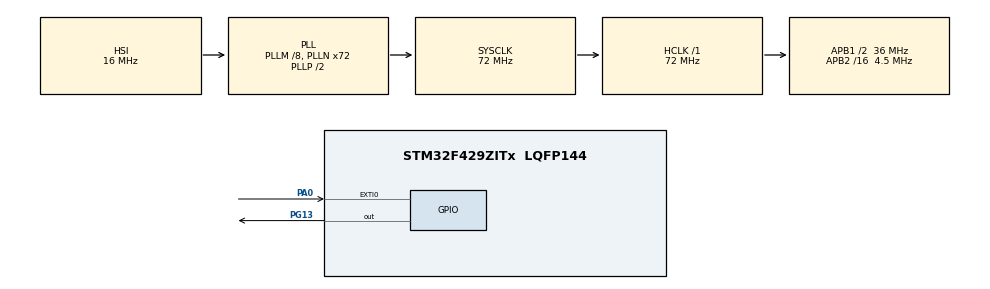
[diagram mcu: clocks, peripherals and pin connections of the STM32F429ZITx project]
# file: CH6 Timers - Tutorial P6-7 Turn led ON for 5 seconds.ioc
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Mcu.Family=STM32F4
Mcu.Name=STM32F429ZITx
Mcu.Package=LQFP144
NVIC.EXTI0_IRQn=true\:0\:0\:false\:false\:true\:true\:true\:true
NVIC.PriorityGroup=NVIC_PRIORITYGROUP_0
NVIC.TIM1_CC_IRQn=true\:0\:0\:false\:false\:true\:true\:true\:true
PA0/WKUP.Signal=GPXTI0
PG13.Signal=GPIO_Output
ProjectManager.HeapSize=0x200
ProjectManager.StackSize=0x400
ProjectManager.TargetToolchain=STM32CubeIDE
RCC.48MHZClocksFreq_Value=20571428.57142857
RCC.AHBFreq_Value=72000000
RCC.APB1CLKDivider=RCC_HCLK_DIV2
RCC.APB1Freq_Value=36000000
RCC.APB1TimFreq_Value=72000000
RCC.APB2CLKDivider=RCC_HCLK_DIV16
RCC.APB2Freq_Value=4500000
RCC.APB2TimFreq_Value=9000000
RCC.CortexFreq_Value=72000000
RCC.HCLKFreq_Value=72000000
RCC.HSE_VALUE=8000000
RCC.HSI_VALUE=16000000
RCC.LSE_VALUE=32768
RCC.PLLM=8
RCC.PLLN=72
RCC.PLLQ=7
RCC.SYSCLKFreq_VALUE=72000000
RCC.SYSCLKSource=RCC_SYSCLKSOURCE_PLLCLK
RCC.VCOOutputFreq_Value=144000000
TIM1.Channel-Output\ Compare1\ No\ Output=TIM_CHANNEL_1
TIM1.Period=20000-1
TIM1.Prescaler=9000-1
TIM1.Pulse-Output\ Compare1\ No\ Output=5000-1
VP_TIM1_VS_ClockSourceINT.Mode=Internal
VP_TIM1_VS_no_output1.Mode=Output Compare1 No Output
board=STM32F429I-DISC1

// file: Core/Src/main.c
/* USER CODE BEGIN Header */
/**
  ******************************************************************************
  * @file           : main.c
  * @brief          : Main program body
  ******************************************************************************
  * @attention
  *
  * Copyright (c) 2023 STMicroelectronics.
  * All rights reserved.
  *
  * This software is licensed under terms that can be found in the LICENSE file
  * in the root directory of this software component.
  * If no LICENSE file comes with this software, it is provided AS-IS.
  *
  ******************************************************************************
  */

 	/* 6 Timers - Problems: ******************************************
	* Tutorial P6-7
	*
	Form a project with the following specifications. When the user presses the
	button on the STM32F4 board, the green LED on the board turns on. The LED
	should turn off after 5 s
	***************************************************************************/
/* USER CODE END Header */
#include "main.h"

TIM_HandleTypeDef htim1;

/* USER CODE BEGIN PV */
uint32_t elapsedtime, TIM_freq;
/* USER CODE END PV */

void SystemClock_Config(void);
static void MX_GPIO_Init(void);
static void MX_TIM1_Init(void);

int main(void)
{

  /* MCU Configuration--------------------------------------------------------*/

  /* Reset of all peripherals, Initializes the Flash interface and the Systick. */
  HAL_Init();

  /* Configure the system clock */
  SystemClock_Config();

  /* Initialize all configured peripherals */
  MX_GPIO_Init();
  MX_TIM1_Init();

  /* Infinite loop */
  while (1)
  {

  }
}

void SystemClock_Config(void)
{
  RCC_OscInitTypeDef RCC_OscInitStruct = {0};
  RCC_ClkInitTypeDef RCC_ClkInitStruct = {0};

  /** Configure the main internal regulator output voltage
  */
  __HAL_RCC_PWR_CLK_ENABLE();
  __HAL_PWR_VOLTAGESCALING_CONFIG(PWR_REGULATOR_VOLTAGE_SCALE3);

  /** Initializes the RCC Oscillators according to the specified parameters
  * in the RCC_OscInitTypeDef structure.
  */
  RCC_OscInitStruct.OscillatorType = RCC_OSCILLATORTYPE_HSI;
  RCC_OscInitStruct.HSIState = RCC_HSI_ON;
  RCC_OscInitStruct.HSICalibrationValue = RCC_HSICALIBRATION_DEFAULT;
  RCC_OscInitStruct.PLL.PLLState = RCC_PLL_ON;
  RCC_OscInitStruct.PLL.PLLSource = RCC_PLLSOURCE_HSI;
  RCC_OscInitStruct.PLL.PLLM = 8;
  RCC_OscInitStruct.PLL.PLLN = 72;
  RCC_OscInitStruct.PLL.PLLP = RCC_PLLP_DIV2;
  RCC_OscInitStruct.PLL.PLLQ = 7;
  if (HAL_RCC_OscConfig(&RCC_OscInitStruct) != HAL_OK)
  {
    Error_Handler();
  }

  /** Initializes the CPU, AHB and APB buses clocks
  */
  RCC_ClkInitStruct.ClockType = RCC_CLOCKTYPE_HCLK|RCC_CLOCKTYPE_SYSCLK
                              |RCC_CLOCKTYPE_PCLK1|RCC_CLOCKTYPE_PCLK2;
  RCC_ClkInitStruct.SYSCLKSource = RCC_SYSCLKSOURCE_PLLCLK;
  RCC_ClkInitStruct.AHBCLKDivider = RCC_SYSCLK_DIV1;
  RCC_ClkInitStruct.APB1CLKDivider = RCC_HCLK_DIV2;
  RCC_ClkInitStruct.APB2CLKDivider = RCC_HCLK_DIV16;

  if (HAL_RCC_ClockConfig(&RCC_ClkInitStruct, FLASH_LATENCY_2) != HAL_OK)
  {
    Error_Handler();
  }
}

static void MX_TIM1_Init(void)
{

  TIM_ClockConfigTypeDef sClockSourceConfig = {0};
  TIM_MasterConfigTypeDef sMasterConfig = {0};
  TIM_OC_InitTypeDef sConfigOC = {0};
  TIM_BreakDeadTimeConfigTypeDef sBreakDeadTimeConfig = {0};

  htim1.Instance = TIM1;
  htim1.Init.Prescaler = 9000-1;
  htim1.Init.CounterMode = TIM_COUNTERMODE_UP;
  htim1.Init.Period = 20000-1;
  htim1.Init.ClockDivision = TIM_CLOCKDIVISION_DIV1;
  htim1.Init.RepetitionCounter = 0;
  htim1.Init.AutoReloadPreload = TIM_AUTORELOAD_PRELOAD_DISABLE;
  if (HAL_TIM_Base_Init(&htim1) != HAL_OK)
  {
    Error_Handler();
  }
  sClockSourceConfig.ClockSource = TIM_CLOCKSOURCE_INTERNAL;
  if (HAL_TIM_ConfigClockSource(&htim1, &sClockSourceConfig) != HAL_OK)
  {
    Error_Handler();
  }
  if (HAL_TIM_OC_Init(&htim1) != HAL_OK)
  {
    Error_Handler();
  }
  sMasterConfig.MasterOutputTrigger = TIM_TRGO_RESET;
  sMasterConfig.MasterSlaveMode = TIM_MASTERSLAVEMODE_DISABLE;
  if (HAL_TIMEx_MasterConfigSynchronization(&htim1, &sMasterConfig) != HAL_OK)
  {
    Error_Handler();
  }
  sConfigOC.OCMode = TIM_OCMODE_TIMING;
  sConfigOC.Pulse = 5000-1;
  sConfigOC.OCPolarity = TIM_OCPOLARITY_HIGH;
  sConfigOC.OCNPolarity = TIM_OCNPOLARITY_HIGH;
  sConfigOC.OCFastMode = TIM_OCFAST_DISABLE;
  sConfigOC.OCIdleState = TIM_OCIDLESTATE_RESET;
  sConfigOC.OCNIdleState = TIM_OCNIDLESTATE_RESET;
  if (HAL_TIM_OC_ConfigChannel(&htim1, &sConfigOC, TIM_CHANNEL_1) != HAL_OK)
  {
    Error_Handler();
  }
  sBreakDeadTimeConfig.OffStateRunMode = TIM_OSSR_DISABLE;
  sBreakDeadTimeConfig.OffStateIDLEMode = TIM_OSSI_DISABLE;
  sBreakDeadTimeConfig.LockLevel = TIM_LOCKLEVEL_OFF;
  sBreakDeadTimeConfig.DeadTime = 0;
  sBreakDeadTimeConfig.BreakState = TIM_BREAK_DISABLE;
  sBreakDeadTimeConfig.BreakPolarity = TIM_BREAKPOLARITY_HIGH;
  sBreakDeadTimeConfig.AutomaticOutput = TIM_AUTOMATICOUTPUT_DISABLE;
  if (HAL_TIMEx_ConfigBreakDeadTime(&htim1, &sBreakDeadTimeConfig) != HAL_OK)
  {
    Error_Handler();
  }

}

static void MX_GPIO_Init(void)
{
  GPIO_InitTypeDef GPIO_InitStruct = {0};

  /* GPIO Ports Clock Enable */
  __HAL_RCC_GPIOA_CLK_ENABLE();
  __HAL_RCC_GPIOG_CLK_ENABLE();

  /*Configure GPIO pin Output Level */
  HAL_GPIO_WritePin(GPIOG, GPIO_PIN_13, GPIO_PIN_RESET);

  /*Configure GPIO pin : PA0 */
  GPIO_InitStruct.Pin = GPIO_PIN_0;
  GPIO_InitStruct.Mode = GPIO_MODE_IT_RISING;
  GPIO_InitStruct.Pull = GPIO_NOPULL;
  HAL_GPIO_Init(GPIOA, &GPIO_InitStruct);

  /*Configure GPIO pin : PG13 */
  GPIO_InitStruct.Pin = GPIO_PIN_13;
  GPIO_InitStruct.Mode = GPIO_MODE_OUTPUT_PP;
  GPIO_InitStruct.Pull = GPIO_NOPULL;
  GPIO_InitStruct.Speed = GPIO_SPEED_FREQ_LOW;
  HAL_GPIO_Init(GPIOG, &GPIO_InitStruct);

  /* EXTI interrupt init*/
  HAL_NVIC_SetPriority(EXTI0_IRQn, 0, 0);
  HAL_NVIC_EnableIRQ(EXTI0_IRQn);

}

/* USER CODE BEGIN 4 */
void HAL_GPIO_EXTI_Callback(uint16_t GPIO_Pin){
	if (GPIO_Pin == GPIO_PIN_0){
		HAL_GPIO_WritePin(GPIOG, GPIO_PIN_13, GPIO_PIN_SET);
		MX_TIM1_Init();
		HAL_TIM_Base_Start(&htim1);
		HAL_TIM_OC_Start_IT(&htim1 , TIM_CHANNEL_1);
	}
}

void HAL_TIM_OC_DelayElapsedCallback(TIM_HandleTypeDef *htim){
	if(HAL_GPIO_ReadPin(GPIOG, GPIO_PIN_13) == GPIO_PIN_SET){

		TIM_freq = (HAL_RCC_GetPCLK2Freq()*2)/ (htim1.Init.Prescaler+1);
		elapsedtime = (__HAL_TIM_GET_COUNTER(&htim1)+1)/ TIM_freq;
		// turn off the led after 5 seconds
		HAL_GPIO_WritePin(GPIOG, GPIO_PIN_13, GPIO_PIN_RESET);
		// Stop the timer and OC interrupt
		HAL_TIM_Base_Stop(&htim1);
		HAL_TIM_OC_Stop_IT(&htim1 , TIM_CHANNEL_1);

	}
}

/* USER CODE END 4 */

void Error_Handler(void)
{
  __disable_irq();
  while (1)
  {
  }
}
